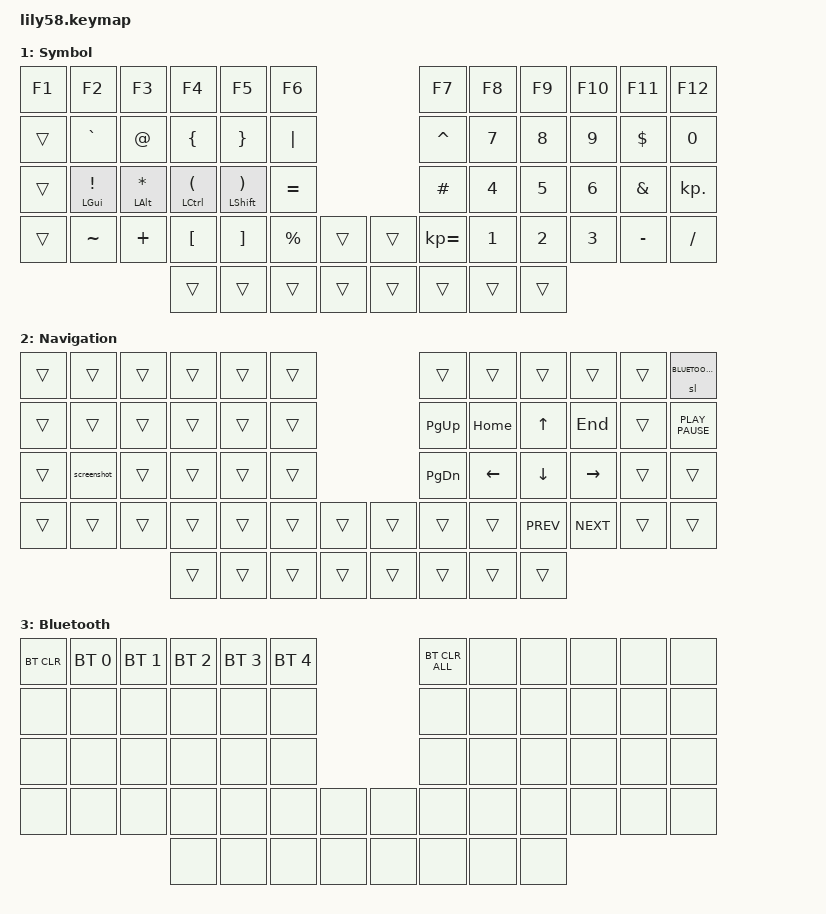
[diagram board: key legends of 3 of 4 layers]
/*
 * Copyright (c) 2020 The ZMK Contributors
 *
 * SPDX-License-Identifier: MIT
 */

#include <behaviors.dtsi>
#include <dt-bindings/zmk/keys.h>
#include <dt-bindings/zmk/bt.h>

#define DEFAULT    0
#define SYMBOL     1
#define NAVIGATION 2
#define BLUETOOTH  3

/ {
    keymap {
        compatible = "zmk,keymap";

        default_layer {
            display-name = "Default";
// ┌─────────┬──────┬──────┬───────────────┬──────┬──────┐                    ┌──────┬──────┬──────┬──────┬──────┬───────┐
// │   ESC   │  1   │  2   │       3       │  4   │  5   │                    │  6   │  7   │  8   │  9   │  0   │   `   │
// ├─────────┼──────┼──────┼───────────────┼──────┼──────┤                    ├──────┼──────┼──────┼──────┼──────┼───────┤
// │   TAB   │  Q   │  W   │  lt(NAV, E)   │  R   │  T   │                    │  Y   │  U   │  I   │  O   │  P   │  td0  │
// ├─────────┼──────┼──────┼───────────────┼──────┼──────┤                    ├──────┼──────┼──────┼──────┼──────┼───────┤
// │   ESC   │GUI/A │ALT/S │    CTRL/D     │SHT/F │SYM/G │                    │SYM/H │SHT/J │CTL/K │ALT/L │GUI/; │ nor_2 │
// ├─────────┼──────┼──────┼───────────────┼──────┼──────┼──────┐  ┌──────┬──────┼──────┼──────┼──────┼──────┼───────┤
// │  none   │  Z   │  X   │       C       │  V   │  B   │ none │  │ none │  N   │  M   │  ,   │  .   │nor_1 │ nor_0 │
// └─────────┴──────┴──────┴───────────────┴──────┴──────┴──────┘  └──────┴──────┴──────┴──────┴──────┴──────┴───────┘
//                       ┌──────┬──────────┬────────┬───────┐           ┌───────┬──────────┬──────┬──────┐
//                       │ LALT │ SPACE    │ LSHIFT │LSHIFT │           │RET    │ RET  │ BSPC │ LGUI │
//                       └──────┴──────────┴────────┴───────┘           └───────┴──────────┴──────┴──────┘
            bindings = <
&kp ESC   &kp N1      &kp N2      &kp N3           &kp N4        &kp N5                              &kp N6       &kp N7        &kp N8        &kp N9       &kp N0          &kp GRAVE
&kp TAB   &kp Q       &kp W       &lt NAVIGATION E &kp R         &kp T                               &kp Y        &kp U         &kp I         &kp O        &kp P           &td0
&kp ESC   &hml LGUI A &hml LALT S &hml LCTRL D     &hml LSHFT F  &lt SYMBOL G                        &lt SYMBOL H &hmr RSHFT J  &hmr RCTRL K  &hmr LALT L  &hmr RGUI SEMI  &nor_2
&none     &kp Z       &kp X       &kp C            &kp V         &kp B    &none         &none        &kp N        &kp M         &kp COMMA     &kp DOT      &nor_1          &nor_0
                                  &kp LALT  &mo NAVIGATION &kp SPACE kp LSHFT             &kp RET  &kp BSPC   &mo SYMBOL      &kp LGUI
            >;

            sensor-bindings = <&inc_dec_kp C_VOL_UP C_VOL_DN>;
        };

        symbol {
            display-name = "Symbol";
// ┌────────┬────────┬──────────┬───────────────┬────────────────┬─────────┐                    ┌──────────┬─────┬─────┬─────┬─────────┬────────┐
// │  F1    │  F2    │   F3     │      F4       │      F5        │   F6    │                    │    F7    │  F8 │  F9 │ F10 │   F11   │  F12   │
// ├────────┼────────┼──────────┼───────────────┼────────────────┼─────────┤                    ├──────────┼─────┼─────┼─────┼─────────┼────────┤
// │ trans  │   `    │    @     │       {       │       }        │    |    │                    │    ^     │  7  │  8  │  9  │    $    │   0    │
// ├────────┼────────┼──────────┼───────────────┼────────────────┼─────────┤                    ├──────────┼─────┼─────┼─────┼─────────┼────────┤
// │ trans  │GUI/!   │ALT/*     │    CTRL/(     │    SHFT/)      │    =    │                    │    #     │  4  │  5  │  6  │    &    │  k,.   │
// ├────────┼────────┼──────────┼───────────────┼────────────────┼─────────┼──────┐  ┌──────┬──────┼─────┼─────┼─────┼─────────┼────────┤
// │ trans  │   ~    │    +     │       [       │       ]        │    %    │trans │  │trans │  =k  │  1  │  2  │  3  │    -    │   /    │
// └────────┴────────┴──────────┴───────────────┴────────────────┴─────────┴──────┘  └──────┴──────┴─────┴─────┴─────┴─────────┴────────┘
            bindings = <
&kp F1  &kp F2          &kp F3            &kp F4                   &kp F5                    &kp F6                                    &kp F7        &kp F8  &kp F9  &kp F10 &kp F11       &kp F12
&trans  &kp GRAVE       &kp AT_SIGN       &kp LEFT_BRACE           &kp RIGHT_BRACE           &kp PIPE                                  &kp CARET     &kp N7  &kp N8  &kp N9  &kp DOLLAR    &kp N0
&trans  &hml LGUI EXCL  &hml LALT ASTRK   &hml LCTRL LPAR          &hml LSHFT RPAR           &kp EQUAL                                 &kp HASH      &kp N4  &kp N5  &kp N6  &kp AMPS      &kp KP_DOT
&trans  &kp TILDE       &kp PLUS          &kp LEFT_BRACKET         &kp RIGHT_BRACKET         &kp PRCNT  &trans        &trans           &kp KP_EQUAL  &kp N1  &kp N2  &kp N3  &kp MINUS     &kp FSLH
                                          &trans                   &trans                    &trans     &trans        &trans           &trans        &trans  &trans
            >;
        };

        navigation {
            display-name = "Navigation";
// ┌────────┬─────┬─────┬─────┬─────┬─────┐                    ┌──────┬──────┬──────┬──────┬─────┬─────────────────┐
// │ trans  │trans│trans│trans│trans│trans│                    │trans │trans │trans │trans │trans│       BT        │
// ├────────┼─────┼─────┼─────┼─────┼─────┤                    ├──────┼──────┼──────┼──────┼─────┼─────────────────┤
// │ trans  │trans│trans│trans│trans│trans│                    │ PgUp │ Home │trans │  End │trans│  K_PLAY_PAUSE   │
// ├────────┼─────┼─────┼─────┼─────┼─────┤                    ├──────┼──────┼──────┼──────┼─────┼─────────────────┤
// │ trans  │trans│trans│trans│trans│trans│trans │  │trans │trans │trans │K_PREV│K_NEXT│trans│      trans      │
// └────────┴─────┴─────┴─────┴─────┴─────┴──────┘  └──────┴──────┴──────┴──────┴──────┴─────┴─────────────────┘
            bindings = <
&trans  &trans       &trans  &trans  &trans  &trans                               &trans     &trans    &trans      &trans      &trans   &sl BLUETOOTH
&trans  &trans       &trans  &trans  &trans  &trans                               &kp PG_UP  &kp HOME  &kp UP      &kp END     &trans   &kp K_PLAY_PAUSE
&trans  &screenshot  &trans  &trans  &trans  &trans                               &kp PG_DN  &kp LEFT  &kp DOWN    &kp RIGHT   &trans   &trans
&trans  &trans       &trans  &trans  &trans  &trans  &trans        &trans         &trans     &trans    &kp K_PREV  &kp K_NEXT  &trans   &trans
                             &trans  &trans  &trans  &trans        &trans         &trans     &trans    &trans
            >;
        };

        bluetooth {
            display-name = "Bluetooth";
            bindings = <
&bt BT_CLR  &bt BT_SEL 0  &bt BT_SEL 1  &bt BT_SEL 2  &bt BT_SEL 3  &bt BT_SEL 4                              &bt BT_CLR_ALL  &none  &none  &none  &none  &none
&none       &none         &none         &none         &none         &none                                       &none           &none  &none  &none  &none  &none
&none       &none         &none         &none         &none         &none                                       &none           &none  &none  &none  &none  &none
&none       &none         &none         &none         &none         &none         &none    &none           &none           &none  &none  &none  &none  &none
                                        &none         &none         &none         &none         &none           &none           &none  &none
            >;
        };
    };

    behaviors {
        hml: home_row_mod_left {
            compatible = "zmk,behavior-hold-tap";
            #binding-cells = <2>;
            flavor = "balanced";
            require-prior-idle-ms = <150>;
            tapping-term-ms = <230>;
            quick-tap-ms = <175>;
            bindings = <&kp>, <&kp>;
        };
        hmr: home_row_mod_right {
            compatible = "zmk,behavior-hold-tap";
            #binding-cells = <2>;
            flavor = "balanced";
            require-prior-idle-ms = <150>;
            tapping-term-ms = <230>;
            quick-tap-ms = <175>;
            bindings = <&kp>, <&kp>;
        };
        td0: quote_bt_tap_dance {
            compatible = "zmk,behavior-tap-dance";
            #binding-cells = <0>;
            tapping-term-ms = <200>;
            bindings = <&kp SINGLE_QUOTE>, <&sl BLUETOOTH>;
        };
    };

    macros {
        /* Norwegian characters */
        nor_0: norwegian_ae {
            compatible = "zmk,behavior-macro";
            #binding-cells = <0>;
            wait-ms = <0>;
            tap-ms = <0>;
            bindings = <&macro_press &kp RALT>
                     , <&macro_tap &kp Z>
                     , <&macro_release &kp RALT>;
        };
        nor_1: norwegian_oe {
            compatible = "zmk,behavior-macro";
            #binding-cells = <0>;
            wait-ms = <0>;
            tap-ms = <0>;
            bindings = <&macro_press &kp RALT>
                     , <&macro_tap &kp L>
                     , <&macro_release &kp RALT>;
        };
        nor_2: norwegian_aa {
            compatible = "zmk,behavior-macro";
            #binding-cells = <0>;
            wait-ms = <0>;
            tap-ms = <0>;
            bindings = <&macro_press &kp RALT>
                     , <&macro_tap &kp W>
                     , <&macro_release &kp RALT>;
        };
        screenshot: screenshot {
            compatible = "zmk,behavior-macro";
            #binding-cells = <0>;
            wait-ms = <0>;
            tap-ms = <0>;
            bindings = <&macro_press &kp LGUI>
                     , <&macro_press &kp LSHFT>
                     , <&macro_tap &kp S>
                     , <&macro_release &kp LGUI>
                     , <&macro_release &kp LSHFT>;
        };

        /* Edit macros */
        copy:  copy_macro  { compatible = "zmk,behavior-macro"; #binding-cells = <0>; bindings = <&kp LC(C)>; };
        cut:   cut_macro   { compatible = "zmk,behavior-macro"; #binding-cells = <0>; bindings = <&kp LC(X)>; };
        paste: paste_macro { compatible = "zmk,behavior-macro"; #binding-cells = <0>; bindings = <&kp LC(V)>; };
    };

    /* Combos – same fingers as on the Corne/Moonlander
     * Key positions (Lily58 row 4 starts at 36):
     *   36=none  37=Z  38=X  39=C  40=V  41=B  42=none | none=43  N=44 ...
     */
    combos {
        compatible = "zmk,combos";
        combo_cut   { timeout-ms = <50>; key-positions = <37 38>; bindings = <&cut>;   }; // Z+X
        combo_copy  { timeout-ms = <50>; key-positions = <38 39>; bindings = <&copy>;  }; // X+C
        combo_paste { timeout-ms = <50>; key-positions = <39 40>; bindings = <&paste>; }; // C+V
    };
};

/* Mechboards lily58 routes nice!view CS to pin 4, not the adapter default (pin 1) */
&nice_view_spi {
    cs-gpios = <&pro_micro 4 GPIO_ACTIVE_HIGH>;
};
